AUTOSAR XML (schema 4-2-2)
package /Components
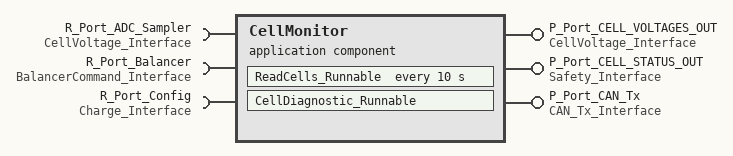
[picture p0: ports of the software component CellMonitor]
  application sw component type CellMonitor
    provide port P_Port_CELL_VOLTAGES_OUT: provided-interface=CellVoltage_Interface
    provide port P_Port_CELL_STATUS_OUT: provided-interface=Safety_Interface
    provide port P_Port_CAN_Tx: provided-interface=CAN_Tx_Interface
    require port R_Port_ADC_Sampler: required-interface=CellVoltage_Interface
    require port R_Port_Balancer: required-interface=BalancerCommand_Interface
    require port R_Port_Config: required-interface=Charge_Interface
    behavior CellMonitor_Behavior
      data received event ADC_Data_Arrived: start-on-event=ReadCells_Runnable
      external trigger occurred event Calibration_Request: start-on-event=CellDiagnostic_Runnable
      timing event Period_10ms: start-on-event=ReadCells_Runnable, period=10
      runnable ReadCells_Runnable: minimum-start-interval=10, symbol=CellMonitor_ReadCells
        data-read-access:
          access Read_ADC_Input: accessed-variable=R_Port_ADC_Sampler.cellVoltages
        data-receive-point-by-arguments:
          access ADC_As_Argument: accessed-variable=R_Port_ADC_Sampler.cellVoltages
        data-send-points:
          access Send_CAN_Frame: accessed-variable=P_Port_CAN_Tx.CAN_Frame
        data-write-access:
          access Write_CellVoltages: accessed-variable=P_Port_CELL_VOLTAGES_OUT.cellVoltages
          access Write_PackVoltage: accessed-variable=P_Port_CELL_VOLTAGES_OUT.packVoltage
      runnable CellDiagnostic_Runnable: minimum-start-interval=1000, symbol=CellMonitor_CellDiagnostic
        data-read-access:
          access Read_History: accessed-variable=P_Port_CELL_VOLTAGES_OUT.cellVoltages
        data-receive-point-by-arguments:
          access Diag_Trigger_Arg: accessed-variable=R_Port_Config.cellVoltageSummary
        data-send-points:
          access Send_CellStatus: accessed-variable=P_Port_CELL_STATUS_OUT.safetyEvent
        data-write-access:
          access Write_SafetyLimits: accessed-variable=P_Port_CELL_STATUS_OUT.safetyLimits
